# STM32MP25_CM33 register map
File version: 1.3
CPU: CM33 r0p1, little endian, MPU, FPU, vendor SysTick, 8 interrupt priority bits
Registers are 32-bit, read-write, reset 0x0 unless marked. A register's access mark holds for its fields unless they carry their own. Offsets are from the block's base; [hi:lo] are bit positions; {n}, {i} and the like mark numbered series; 'fields as' and 'values as' point back to an identical list.

## RCC (part 1 of 3) — RCC register block
Base 0x44200000
Same registers: RCC_S 0x54200000
0x00 RCC_SECCFGR0 — RCC secure configuration register 0
  [31:0] SEC — Secure attribute reference for local resource number x
    0=Secure and non-secure data accesses are granted to local resource number x; 1=Only secure data access is granted to local resource number x
0x04 RCC_SECCFGR1 — RCC secure configuration register 1
  [31:0] SEC — Secure attribute reference for the local resource number x
    values as RCC_SECCFGR0.SEC
0x08 RCC_SECCFGR2 — RCC secure configuration register 2
  [31:0] SEC — Secure attribute reference for the local resource number x
    0=Non-secure write access is allowed; 1=Only secure write access is allowed
0x0C RCC_SECCFGR3 — RCC secure configuration register 3
  [17:0] SEC — Secure attribute reference for the local resource number x
    0=Non-secure write access is allowed; 1=Secure write access is allowed
0x10 RCC_PRIVCFGR0 — RCC privileged configuration register 0
  [31:0] PRIV — Privileged attribute reference for local resource number x
    0=Privileged and unprivileged data accesses are granted to local resource number x; 1=Only privileged data access is granted to local resource number x
0x14 RCC_PRIVCFGR1 — RCC privileged configuration register 1
  [31:0] PRIV — Privileged attribute reference for the local resource number x
    values as RCC_PRIVCFGR0.PRIV
0x18 RCC_PRIVCFGR2 — RCC privileged configuration register 2
  fields as RCC_PRIVCFGR1
0x1C RCC_PRIVCFGR3 — RCC privileged configuration register 3
  [17:0] PRIV — Privileged attribute reference for the local resource number x
    values as RCC_PRIVCFGR0.PRIV
0x20 RCC_RCFGLOCKR0 — RCC resource configuration lock register 0
  [31:0] RLOCK — RCC local resource number x lock
    0=SECx in RCC_SECCFGR0 and PRIVx in RCC_PRIVCFGR0 are writable; 1=Writes to SECx in RCC_SECCFGR0 and PRIVx in RCC_PRIVCFGR0 are ignored
0x24 RCC_RCFGLOCKR1 — RCC resource configuration lock register 1
  [31:0] RLOCK — RCC local resource number x lock
    0=SEC(x - 32) in RCC_SECCFGR1 and PRIV(x - 32) in RCC_PRIVCFGR1 are writable; 1=Writes to SEC(x - 32) in RCC_SECCFGR1 and PRIV(x - 32) in RCC_PRIVCFGR1 are ignored
0x28 RCC_RCFGLOCKR2 — RCC resource configuration lock register 2
  [31:0] RLOCK — RCC local resource number x lock
    0=SEC(x - 64) in RCC_SECCFGR2 and PRIV(x - 64) in RCC_PRIVCFGR2 are writable; 1=Writes to SEC(x - 64) in RCC_SECCFGR2 and PRIV(x - 64) in RCC_PRIVCFGR2 are ignored
0x2C RCC_RCFGLOCKR3 — RCC resource configuration lock register 3
  [17:0] RLOCK — RCC local resource number x lock
    0=SEC(x - 96) in RCC_SECCFGR3 and PRIV(x - 96) in RCC_PRIVCFGR3 are writable; 1=Writes to SEC(x - 96) in RCC_SECCFGR3 and PRIV(x - 96) in RCC_PRIVCFGR3 are ignored
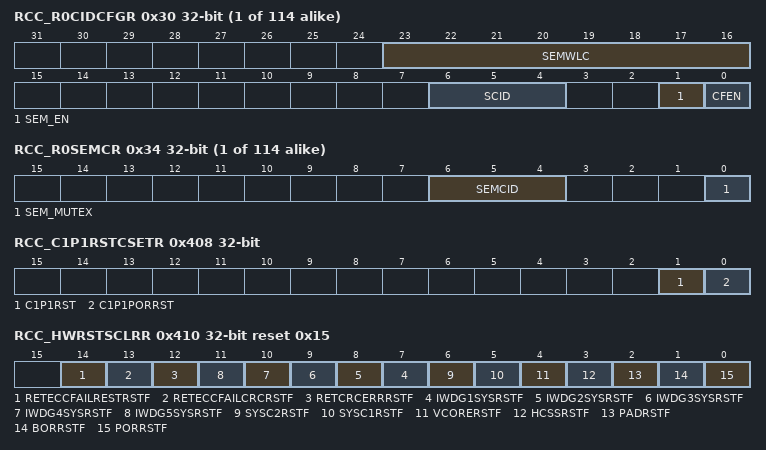
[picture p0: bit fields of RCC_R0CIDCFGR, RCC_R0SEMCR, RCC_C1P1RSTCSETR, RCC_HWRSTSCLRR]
{0x30+8i} RCC_R{i}CIDCFGR (i=0..113) — RCC resource {i} CID configuration register
  [23:16] SEMWLC — Semaphore white-list for compartment y
    0=Application running in compartment y cannot get access to local resource x through semaphore SEM_MUTEX; 1=Application running in compartment y can get access to local resource x through semaphore SEM_MUTEX
  [6:4] SCID — Static compartment ID
  [1] SEM_EN — Semaphore enable
    0=Access to local resource x is granted only if CID of the access equals to SCID; 1=Access to local resource x is granted only if SEM_MUTEX = 1, and CID of the access equals to SEMCID
  [0] CFEN — Static CID filter enable
    0=Compartment-based filtering is defined in RCC_RxCIDCFGR, and optionally RCC_RxSEMCR is disabled for local resource x; 1=Compartment-based filtering is defined in RCC_RxCIDCFGR, and optionally RCC_RxSEMCR is enabled for local resource x
{0x34+8i} RCC_R{i}SEMCR (i=0..113) — RCC resource {i} semaphore control register
  [6:4] SEMCID ro — Semaphore compartment ID
  [0] SEM_MUTEX — Semaphore mutex
    0=Reading 0 means that the semaphore is free; 1=Reading 1 means that the semaphore is taken
0x400 RCC_GRSTCSETR — RCC global reset control set register
  [0] SYSRST — System reset
    0=Writing 0 has no effect; 1=Writing 1 generates a system reset (see Figure80)
0x404 RCC_C1RSTCSETR — RCC CPU1 reset control set register
  [0] C1RST — CPU1 reset
    0=Writing 0 has no effect; 1=Writing 1 generates a CPU1 reset
0x408 RCC_C1P1RSTCSETR — RCC CPU1 processor core 1 reset control set register
  [1] C1P1RST — CPU1 processor core 1 reset
    0=Writing 0 has no effect; 1=Writing 1 generates a CPU1 processor core 1 reset
  [0] C1P1PORRST — CPU1 processor core 1 power-on reset
    0=Writing 0 has no effect; 1=Writing 1 generates a CPU1 processor core 1 power-on reset
0x40C RCC_C2RSTCSETR — RCC CPU2 reset control set register
  [0] C2RST — CPU2 reset
    0=Writing 0 has no effect; 1=Writing 1 generates a CPU2 reset
0x410 RCC_HWRSTSCLRR reset 0x15 — RCC hardware reset status clear register
  [14] RETECCFAILRESTRSTF — RETRAM ECC failure reset flag during system restoration phase
    0=Writing 0 has no effect; 1=Writing 1 clears the RETECCFAILRESTRSTF flag
  [13] RETECCFAILCRCRSTF — RETRAM ECC failure reset flag during the CRC computation phase
    0=Writing 0 has no effect; 1=Writing 1 clears the RETECCFAILCRCRSTF flag
  [12] RETCRCERRRSTF — RETRAM CRC error reset flag
    0=Writing 0 has no effect; 1=Writing 1 clears the RETCRCERRRSTF flag
  [n+6] IWDG{n}SYSRSTF (n=1..5) — IWDG{n} system reset flag
    0=Writing 0 has no effect; 1=Writing 1 clears the IWDG{n}SYSRSTF flag
  [6] SYSC2RSTF — CPU2 system reset flag
    0=Writing 0 has no effect; 1=Writing 1 clears the SYSC2RSTF flag
  [5] SYSC1RSTF — CPU1 system reset flag
    0=Writing 0 has no effect; 1=Writing 1 clears the SYSC1RSTF flag
  [4] VCORERSTF — Vless thansub>DDCOREless than/sub> reset flag
    0=Writing 0 has no effect; 1=Writing 1 clears the VCORERSTF flag
  [3] HCSSRSTF — HSE CSS reset flag
    0=Writing 0 has no effect; 1=Writing 1 clears the HCSSRSTF flag
  [2] PADRSTF — NRST reset flag
    0=Writing 0 has no effect; 1=Writing 1 clears the PADRSTF flag
  [1] BORRSTF — BOR reset flag
    0=Writing 0 has no effect; 1=Writing 1 clears the BORRSTF flag
  [0] PORRSTF — POR/PDR reset flag
    0=Writing 0 has no effect; 1=Writing 1 clears the PORRSTF flag
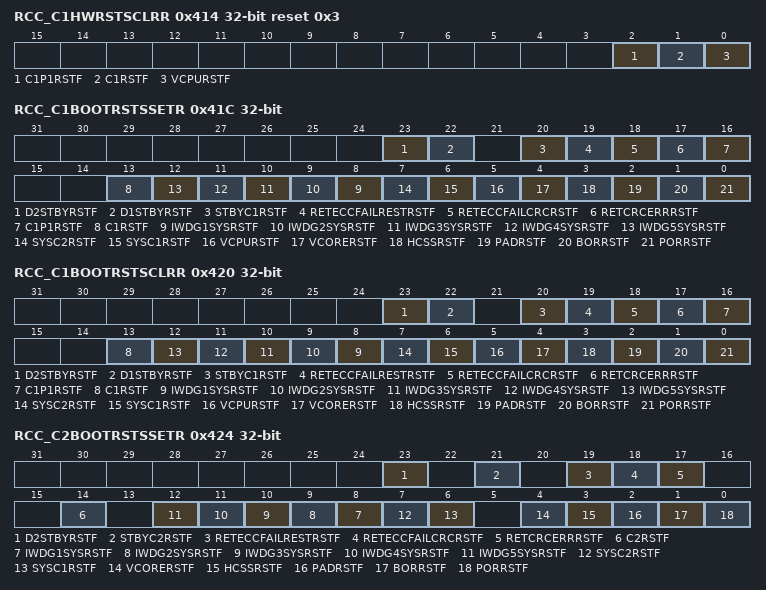
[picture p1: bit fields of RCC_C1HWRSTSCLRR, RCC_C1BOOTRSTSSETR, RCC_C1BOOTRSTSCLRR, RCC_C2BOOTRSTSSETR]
0x414 RCC_C1HWRSTSCLRR reset 0x3 — RCC CPU1 hardware reset status clear register
  [2] C1P1RSTF — CPU1 processor core 1 reset flag
    0=Writing 0 has no effect; 1=Writing 1 clears the C1P1RSTF flag
  [1] C1RSTF — CPU1 reset flag
    0=Writing 0 has no effect; 1=Writing 1 clears the C1RSTF flag
  [0] VCPURSTF — Vless thansub>DDCPUless than/sub> reset flag
    0=Writing 0 has no effect; 1=Writing 1 clears the VCPURSTF flag
0x418 RCC_C2HWRSTSCLRR reset 0x1 — RCC CPU2 hardware reset status clear register
  [0] C2RSTF — CPU2 reset flag
    0=Writing 0 has no effect; 1=Writing 1 clears the C2RSTF flag
0x41C RCC_C1BOOTRSTSSETR — RCC CPU1 boot reset status set register
  [23] D2STBYRSTF — D2 DStandby reset flag
    0=No effect; 1=Set the D2STBYRSTF bit
  [22] D1STBYRSTF — D1 DStandby reset flag
    0=No effect; 1=Set the D1STBYRSTF bit
  [20] STBYC1RSTF — CPU1 system Standby reset flag
    0=No effect; 1=Set the STBYC1RSTF bit
  [19] RETECCFAILRESTRSTF — RETRAM ECC failure reset flag during system restoration phase
    0=No effect; 1=Set the RETECCFAILRESTRSTF bit
  [18] RETECCFAILCRCRSTF — RETRAM ECC failure reset flag during the CRC computation phase
    0=No effect; 1=Set the RETECCFAILCRCRSTF bit
  [17] RETCRCERRRSTF — RETRAM CRC error reset flag
    0=No effect; 1=Set the RETCRCERRRSTF bit
  [16] C1P1RSTF — CPU1 processor core 1 reset flag
    0=No effect; 1=Set the C1P1RSTF bit
  [13] C1RSTF — CPU1 reset flag
    0=No effect; 1=Set the C1RSTF bit
  [n+7] IWDG{n}SYSRSTF (n=1..5) — IWDG{n} system reset flag
    0=No effect; 1=Set the IWDG{n}SYSRSTF bit
  [7] SYSC2RSTF — CPU2 system reset flag
    0=No effect; 1=Set the SYSC2RSTF bit
  [6] SYSC1RSTF — CPU1 system reset flag
    0=No effect; 1=Set the SYSC1RSTF bit
  [5] VCPURSTF — Vless thansub>DDCPUless than/sub> reset flag
    0=No effect; 1=Set the VCPURSTF bit
  [4] VCORERSTF — Vless thansub>DDCOREless than/sub> reset flag
    0=No effect; 1=Set the VCORERSTF bit
  [3] HCSSRSTF — HSE CSS reset flag
    0=No effect; 1=Set the HCSSRSTF bit
  [2] PADRSTF — NRST reset flag
    0=No effect; 1=Set the PADRSTF bit
  [1] BORRSTF — BOR reset flag
    0=No effect; 1=Set the BORRSTF bit
  [0] PORRSTF — POR/PDR reset flag
    0=No effect; 1=Set the PORRSTF bit
0x420 RCC_C1BOOTRSTSCLRR — RCC CPU1 boot reset status clear register
  [23] D2STBYRSTF — D2 DStandby reset flag
    0=No effect; 1=Clear the D2STBYRSTF bit
  [22] D1STBYRSTF — D1 DStandby reset flag
    0=No effect; 1=Clear the D1STBYRSTF bit
  [20] STBYC1RSTF — CPU1 system Standby reset flag
    0=No effect; 1=Clear the STBYC1RSTF bit
  [19] RETECCFAILRESTRSTF — RETRAM ECC failure reset flag during system restoration phase
    0=No effect; 1=Clear the RETECCFAILRESTRSTF bit
  [18] RETECCFAILCRCRSTF — RETRAM ECC failure reset flag during the CRC computation phase
    0=No effect; 1=Clear the RETECCFAILCRCRSTF bit
  [17] RETCRCERRRSTF — RETRAM CRC error reset flag
    0=No effect; 1=Clear the RETCRCERRRSTF bit
  [16] C1P1RSTF — CPU1 processor core 1 reset flag
    0=No effect; 1=Clear the C1P1RSTF bit
  [13] C1RSTF — CPU1 reset flag
    0=No effect; 1=Clear the C1RSTF bit
  [n+7] IWDG{n}SYSRSTF (n=1..5) — IWDG{n} system reset flag
    0=No effect; 1=Clear the IWDG{n}SYSRSTF bit
  [7] SYSC2RSTF — CPU2 system reset flag
    0=No effect; 1=Clear the SYSC2RSTF bit
  [6] SYSC1RSTF — CPU1 system reset flag
    0=No effect; 1=Clear the SYSC1RSTF bit
  [5] VCPURSTF — Vless thansub>DDCPUless than/sub> reset flag
    0=No effect; 1=Clear the VCPURSTF bit
  [4] VCORERSTF — Vless thansub>DDCOREless than/sub> reset flag
    0=No effect; 1=Clear the VCORERSTF bit
  [3] HCSSRSTF — HSE CSS reset flag
    0=No effect; 1=Clear the HCSSRSTF bit
  [2] PADRSTF — NRST reset flag
    0=No effect; 1=Clear the PADRSTF bit
  [1] BORRSTF — BOR reset flag
    0=No effect; 1=Clear the BORRSTF bit
  [0] PORRSTF — POR/PDR reset flag
    0=No effect; 1=Clear the PORRSTF bit
0x424 RCC_C2BOOTRSTSSETR — RCC CPU2 boot reset status set register
  [23] D2STBYRSTF — D2 DStandby reset flag
    0=No effect; 1=Set the D2STBYRSTF bit
  [21] STBYC2RSTF — CPU2 system Standby reset flag
    0=No effect; 1=Set the STBYC2RSTF bit
  [19] RETECCFAILRESTRSTF — RETRAM ECC failure reset flag during system restoration phase
    0=No effect; 1=Set the RETECCFAILRESTRSTF bit
  [18] RETECCFAILCRCRSTF — RETRAM ECC failure reset flag during the CRC computation phase
    0=No effect; 1=Set the RETECCFAILCRCRSTF bit
  [17] RETCRCERRRSTF — RETRAM CRC error reset flag
    0=No effect; 1=Set the RETCRCERRRSTF bit
  [14] C2RSTF — CPU2 reset flag
    0=No effect; 1=Set the C2RSTF bit
  [n+7] IWDG{n}SYSRSTF (n=1..5) — IWDG{n} system reset flag
    0=No effect; 1=Set the IWDG{n}SYSRSTF bit
  [7] SYSC2RSTF — CPU2 system reset flag
    0=No effect; 1=Set the SYSC2RSTF bit
  [6] SYSC1RSTF — CPU1 system reset flag
    0=No effect; 1=Set the SYSC1RSTF bit
  [4] VCORERSTF — Vless thansub>DDCOREless than/sub> reset flag
    0=No effect; 1=Set the VCORERSTF bit
  [3] HCSSRSTF — HSE CSS reset flag
    0=No effect; 1=Set the HCSSRSTF bit
  [2] PADRSTF — NRST reset flag
    0=No effect; 1=Set the PADRSTF bit
  [1] BORRSTF — BOR reset flag
    0=No effect; 1=Set the BORRSTF bit
  [0] PORRSTF — POR/PDR reset flag
    0=No effect; 1=Set the PORRSTF bit
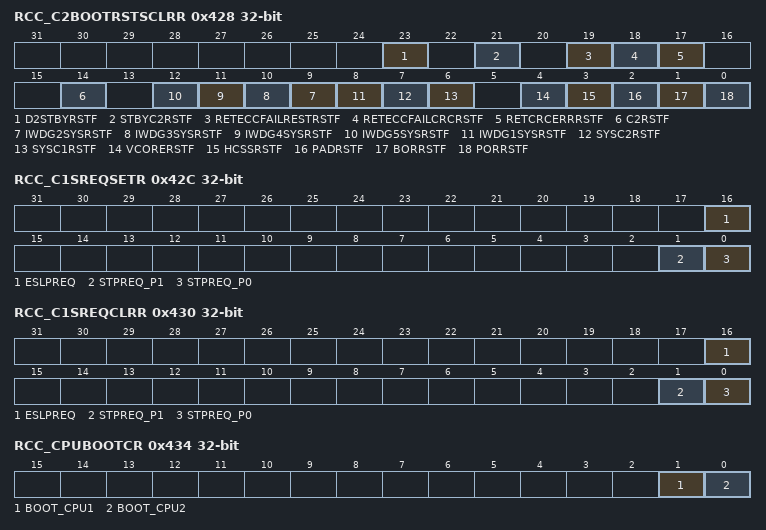
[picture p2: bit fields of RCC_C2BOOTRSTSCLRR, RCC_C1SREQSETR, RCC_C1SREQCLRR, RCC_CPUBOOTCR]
0x428 RCC_C2BOOTRSTSCLRR — RCC CPU2 boot reset status clear register
  [23] D2STBYRSTF — D2 DStandby reset flag
    0=No effect; 1=Clear the D2STBYRSTF bit
  [21] STBYC2RSTF — CPU2 system Standby reset flag
    0=No effect; 1=Clear the STBYC2RSTF bit
  [19] RETECCFAILRESTRSTF — RETRAM ECC failure reset flag during system restoration phase
    0=No effect; 1=Clear the RETECCFAILRESTRSTF bit
  [18] RETECCFAILCRCRSTF — RETRAM ECC failure reset flag during the CRC computation phase
    0=No effect; 1=Clear the RETECCFAILCRCRSTF bit
  [17] RETCRCERRRSTF — RETRAM CRC error reset flag
    0=No effect; 1=Clear the RETCRCERRRSTF bit
  [14] C2RSTF — CPU2 reset flag
    0=No effect; 1=Clear the C2RSTF bit
  [n+7] IWDG{n}SYSRSTF (n=2..5) — IWDG{n} reset flag
    0=No effect; 1=Clear the IWDG{n}SYSRSTF bit
  [8] IWDG1SYSRSTF — IWDG1 system reset flag
    0=No effect; 1=Clear the IWDG1SYSRSTF bit
  [7] SYSC2RSTF — CPU2 system reset flag
    0=No effect; 1=Clear the SYSC2RSTF bit
  [6] SYSC1RSTF — CPU1 system reset flag
    0=No effect; 1=Clear the SYSC1RSTF bit
  [4] VCORERSTF — Vless thansub>DDCOREless than/sub> reset flag
    0=No effect; 1=Clear the VCORERSTF bit
  [3] HCSSRSTF — HSE CSS reset flag
    0=No effect; 1=Clear the HCSSRSTF bit
  [2] PADRSTF — NRST reset flag
    0=No effect; 1=Clear the PADRSTF bit
  [1] BORRSTF — BOR reset flag
    0=No effect; 1=Clear the BORRSTF bit
  [0] PORRSTF — POR/PDR reset flag
    0=No effect; 1=Clear the PORRSTF bit
0x42C RCC_C1SREQSETR — RCC CPU1 stop request set register
  [16] ESLPREQ — Enhanced CSleep request for CPU1 subsystem
    0=Writing 0 has no effect; 1=Writing 1 sets the ESLPREQ bit
  [1] STPREQ_P1 — Stop request for CPU1 processor core 1
    0=Writing 0 has no effect; 1=Writing 1 sets the STPREQ_P1 bit
  [0] STPREQ_P0 — Stop request for CPU1 processor core 0
    0=Writing 0 has no effect; 1=Writing 1 sets the STPREQ_P0 bit
0x430 RCC_C1SREQCLRR — RCC CPU1 stop request clear register
  [16] ESLPREQ — Enhanced CSleep request for CPU1 subsystem
    0=Writing 0 has no effect; 1=Writing 1 clears the ESLPREQ bit
  [1] STPREQ_P1 — Stop request for CPU1 processor core 1
    0=Writing 0 has no effect; 1=Writing 1 clears the STPREQ_P1 bit
  [0] STPREQ_P0 — Stop request for CPU1 processor core 0
    0=Writing 0 has no effect; 1=Writing 1 clears the STPREQ_P0 bit
0x434 RCC_CPUBOOTCR — RCC CPU boot control register
  [1] BOOT_CPU1 — CPU1 boot
    0=The CPU1 is set in HOLD_BOOT when the next CPU1 reset occurs; 1=The CPU1 is not in HOLD_BOOT mode when the next CPU1 reset occurs
  [0] BOOT_CPU2 — CPU2 to boot
    0=The CPU2 is set in HOLD_BOOT when the next CPU2 core reset occurs; 1=The CPU2 is not in HOLD_BOOT mode when the next CPU2 core reset occurs
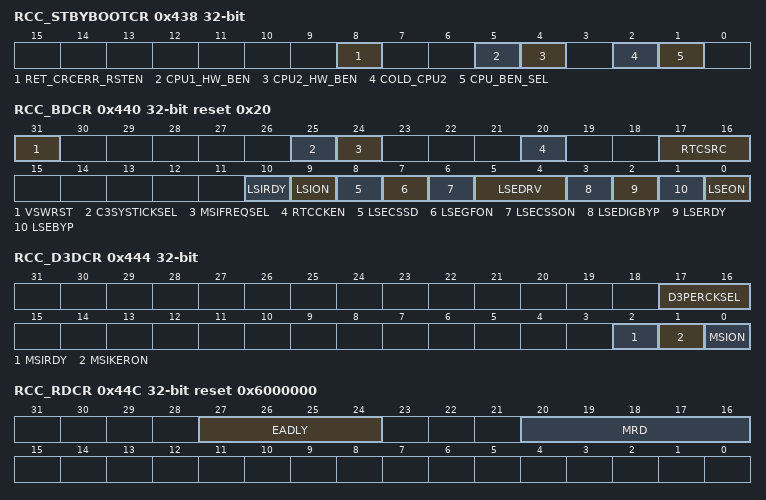
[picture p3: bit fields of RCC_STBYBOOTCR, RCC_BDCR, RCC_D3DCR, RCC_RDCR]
0x438 RCC_STBYBOOTCR rw-once — RCC standby boot control register
  [8] RET_CRCERR_RSTEN rw — RETRAM CRC error system reset enable
    0=RETRAM CRC error does not trigger a system reset (default after reset); 1=RETRAM CRC error triggers a system reset
  [5] CPU1_HW_BEN ro — CPU1 hardware boot enable
    0=CPU1 remains in HOLD_BOOT state; 1=CPU1 is allowed to restart
  [4] CPU2_HW_BEN ro — CPU2 hardware boot enable
    0=CPU2 remains in HOLD_BOOT state; 1=CPU2 is allowed to restart
  [2] COLD_CPU2 — CPU2 cold boot
    0=CPU1 is the cold boot CPU; 1=CPU2 is the cold boot CPU
  [1] CPU_BEN_SEL rw — CPU boot select
    0=CPU1 restarts first (default after reset); 1=CPU2 restarts first
0x43C RCC_LEGBOOTCR rw-once — RCC legacy boot control register
  [0] LEGACY_BEN — Enable of the legacy selection mode to choose the first CPU to boot
    0=The legacy selection mode is disabled (default after reset); 1=The legacy selection mode is enabled
0x440 RCC_BDCR rw-once reset 0x20 — RCC backup domain control register
  [31] VSWRST rw — Vless thansub>SWless than/sub> domain software reset
    0=Reset not activated (default after backup domain reset); 1=Resets the entire Vless thansub>SWless than/sub> domain
  [25] C3SYSTICKSEL rw — CPU3 SysTick clock select
    0=CPU3 SysTick clock is LSI (default after backup domain reset); 1=CPU3 SysTick clock is LSE
  [24] MSIFREQSEL rw — MSI frequency selection
    0=MSI frequency is 4 MHz (default after backup domain reset); 1=MSI frequency is 16 MHz
  [20] RTCCKEN rw — RTC clock enable
    0=rtc_ck clock disabled (default after backup domain reset); 1=rtc_ck clock enabled
  [17:16] RTCSRC — RTC clock source selection
    0=No clock (default after backup domain reset); 1=LSE clock used as RTC clock; 2=LSI clock used as RTC clock; 3=HSE clock divided by RTCDIV value used as RTC clock
  [10] LSIRDY ro — LSI oscillator ready
    0=LSI oscillator not ready (default after reset); 1=LSI oscillator ready
  [9] LSION rw — LSI oscillator enabled
    0=LSI oscillator off (default after backup domain reset); 1=LSI oscillator on
  [8] LSECSSD ro — LSE CSS failure detection
    0=No failure detected on 32 kHz oscillator (default after backup domain reset); 1=Failure detected on 32 kHz oscillator
  [7] LSEGFON rw — LSE clock glitch filter enable
    0=LSE clock glitch filter disabled; 1=LSE clock glitch filter enabled
  [6] LSECSSON rw — LSE CSS enable
    0=CSS on 32 kHz oscillator off (default after backup domain reset); 1=CSS on 32 kHz oscillator on
  [5:4] LSEDRV rw — LSE oscillator driving capability
    0=Lowest drive; 1=Medium-low drive; 2=Medium-high drive (default after backup domain reset); 3=Highest drive
  [3] LSEDIGBYP rw — LSE digital bypass
    0=LSE in analog bypass mode (default after backup domain reset); 1=LSE in digital bypass mode
  [2] LSERDY ro — LSE oscillator ready
    0=LSE oscillator not ready (default after backup domain reset); 1=LSE oscillator ready
  [1] LSEBYP rw — LSE oscillator bypass
    0=LSE oscillator not bypassed (default after backup domain reset); 1=LSE oscillator bypassed
  [0] LSEON rw — LSE oscillator enable
    0=LSE oscillator off (default after backup domain reset); 1=LSE oscillator on
0x444 RCC_D3DCR — RCC D3 domain control register
  [17:16] D3PERCKSEL — D3 peripheral local bus clock select
    0=MSI kernel clock used as D3 peripheral bus clock interface; 1=LSI clock used as D3 peripheral bus clock interface; 2=LSE clock used as D3 peripheral bus clock interface
  [2] MSIRDY ro — MSI clock ready flag
    0=MSI clock is not ready (default after reset); 1=MSI clock is ready
  [1] MSIKERON — Set by software to force the MSI on, even in Stop mode, in order to be quickly available as kernel clock for some peripherals.
    0=No effect; 1=Set the MSIKERON bit
  [0] MSION — MSI oscillator enable
    0=MSI oscillator off (default after reset); 1=MSI oscillator on
0x448 RCC_D3DSR ro — RCC D3 domain status register
  [1:0] D3STATE — D3 domain state
    0=D3 domain in reset state (default after reset); 1=D3 domain in system state (flexclkgen clocking); 2=D3 domain in clock switching state; 3=D3 domain in local state (D3 local clocking)
0x44C RCC_RDCR reset 0x6000000 — RCC reset duration control register
  [27:24] EADLY — External access delays
    0=No extra delay added by boot ROM; 1=100 us; 2=200 us; 3=500 us; 4=1 ms; 5=2 ms; 6=5 ms (default after reset); 7=10 ms; 8=20 ms; 9=50 ms; 10=100 ms; 11=200 ms; 12=500 ms; 13=1 s; 14=2 s; 15=5 s
  [20:16] MRD — Minimum reset duration
    0=NRST low-pulse duration is guaranteed by the pulse stretcher of the pin; 1=The guaranteed NRST low-pulse duration is about 1 ms (1 x 32 lsi_ck cycles); 2=The guaranteed NRST low-pulse duration is about 2 ms (2 x 32 lsi_ck cycles); 31=The guaranteed NRST low-pulse duration is about 31 ms (31 x 32 lsi_ck cycles)
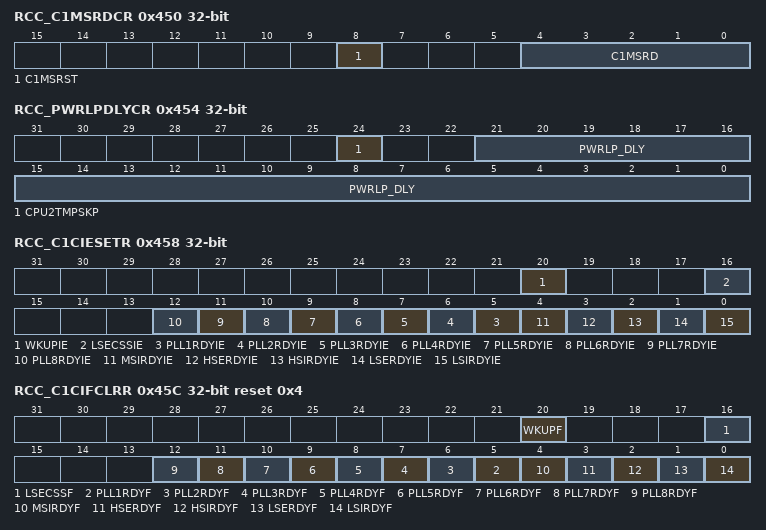
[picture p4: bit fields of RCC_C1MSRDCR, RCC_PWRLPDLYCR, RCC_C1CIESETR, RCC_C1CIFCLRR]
0x450 RCC_C1MSRDCR — RCC C1MS reset delay control register
  [8] C1MSRST — Trigger low-level pulse on NRSTC1MS pin
    0=Reading 0 means that the NRSTC1MS level is high (inactive) (default after reset); 1=Writing 1 triggers a low-level pulse on NRSTC1MS according to C1MSRD value
  [4:0] C1MSRD — Minimum Standby reset duration
    0=No pulse on NRSTC1MS (default after reset); 1=The guaranteed NRSTC1MS low-pulse duration is about 1 ms (1 x 32 lsi_ck cycles); 2=The guaranteed NRSTC1MS low-pulse duration is about 2 ms (2 x 32 lsi_ck cycles); 31=The guaranteed NRSTC1MS low-pulse duration is about 31 ms (31 x 32 lsi_ck cycles)
0x454 RCC_PWRLPDLYCR — RCC PWR_LP delay control register
  [24] CPU2TMPSKP — Skip of PWR_LP delay for CPU2
    0=The CPU2 clock restore sequence waits for the PWR_LP delay before activating power consuming elements (default after reset); 1=The CPU2 clock restore sequence runs the PWR_LP delay, but did not wait for the delay to elapse before activating power consuming elements
  [21:0] PWRLP_DLY — PWR_LP delay value
    0=PWR_LP delay bypassed (default after reset); 1=PWR_LP delay of one 64 MHz HSI period (LSMCU = 0) or two HSI periods; 0x3FFFFF=PWR_LP delay of about 65
0x458 RCC_C1CIESETR — RCC CPU1 clock source interrupt enable set register
  [20] WKUPIE — CPU1 wake-up from CStop interrupt enable
    0=Wake-up interrupt disabled (default after reset); 1=Wake-up interrupt enabled
  [16] LSECSSIE — LSE clock security system interrupt enable
    0=LSE CSS interrupt disabled (default after reset); 1=LSE CSS interrupt enabled
  [n+4] PLL{n}RDYIE (n=1..8) — PLL{n} ready interrupt enable
    0=PLL{n} lock interrupt disabled (default after reset); 1=PLL{n} lock interrupt enabled
  [4] MSIRDYIE — MSI ready interrupt enable
    0=MSI ready interrupt disabled (default after reset); 1=MSI ready interrupt enabled
  [3] HSERDYIE — HSE ready interrupt enable
    0=HSE ready interrupt disabled (default after reset); 1=HSE ready interrupt enabled
  [2] HSIRDYIE — HSI ready interrupt enable
    0=HSI ready interrupt disabled (default after reset); 1=HSI ready interrupt enabled
  [1] LSERDYIE — LSE ready interrupt enable
    0=LSE ready interrupt disabled (default after reset); 1=LSE ready interrupt enabled
  [0] LSIRDYIE — LSI ready interrupt enable
    0=LSI ready interrupt disabled (default after reset); 1=LSI ready interrupt enabled
0x45C RCC_C1CIFCLRR reset 0x4 — RCC CPU1 clock source interrupt flag clear register
  [20] WKUPF — CPU1 wake-up from CStop interrupt flag
    0=No wake-up interrupt pending (default after reset); 1=Wake-up interrupt pending
  [16] LSECSSF — LSE CSS interrupt flag
    0=No failure detected on the external 32 kHz oscillator (default after reset); 1=A failure is detected on the external 32 kHz oscillator
  [n+4] PLL{n}RDYF (n=1..8) — PLL{n} ready interrupt flag
    0=No clock ready interrupt caused by PLL{n} lock (default after reset); 1=Clock ready interrupt caused by PLL{n} lock
  [4] MSIRDYF — MSI ready interrupt flag
    0=No clock ready interrupt caused by the MSI (default after reset); 1=Clock ready interrupt caused by the MSI
  [3] HSERDYF — HSE ready interrupt flag
    0=No clock ready interrupt caused by the HSE (default after reset); 1=Clock ready interrupt caused by the HSE
  [2] HSIRDYF — HSI ready interrupt flag
    0=No clock ready interrupt caused by the HSI (default after reset); 1=Clock ready interrupt caused by the HSI
  [1] LSERDYF — LSE ready interrupt flag
    0=No clock ready interrupt caused by the LSE (default after reset); 1=Clock ready interrupt caused by the LSE
  [0] LSIRDYF — LSI ready interrupt flag
    0=No clock ready interrupt caused by the LSI (default after reset); 1=Clock ready interrupt caused by the LSI
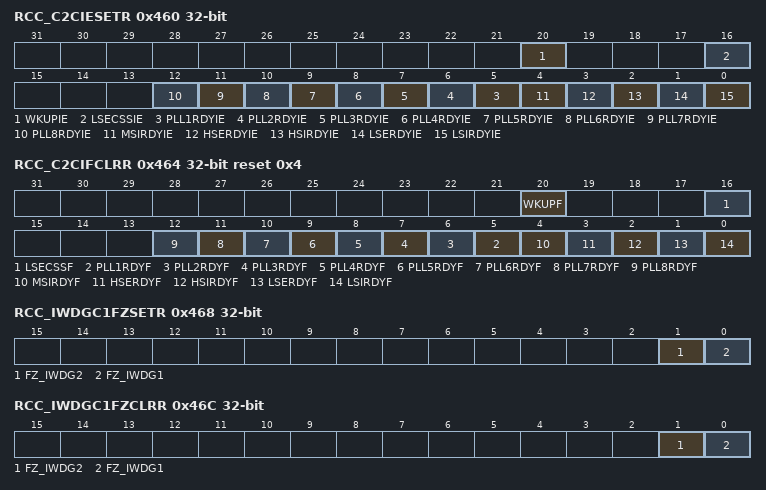
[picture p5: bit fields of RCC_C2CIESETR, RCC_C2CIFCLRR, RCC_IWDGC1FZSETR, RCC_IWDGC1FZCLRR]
0x460 RCC_C2CIESETR — RCC CPU2 clock source interrupt enable set register
  [20] WKUPIE — CPU2 wake-up from CStop Interrupt Enable
    values as RCC_C1CIESETR.WKUPIE
  [16] LSECSSIE — LSE CSS interrupt enable
    values as RCC_C1CIESETR.LSECSSIE
  [n+4] PLL{n}RDYIE (n=1..8) — PLL{n} ready interrupt enable
    values as RCC_C1CIESETR.PLL1RDYIE
  [4] MSIRDYIE — MSI ready interrupt enable
    values as RCC_C1CIESETR.MSIRDYIE
  [3] HSERDYIE — HSE ready interrupt enable
    values as RCC_C1CIESETR.HSERDYIE
  [2] HSIRDYIE — HSI ready interrupt enable
    values as RCC_C1CIESETR.HSIRDYIE
  [1] LSERDYIE — LSE ready interrupt enable
    values as RCC_C1CIESETR.LSERDYIE
  [0] LSIRDYIE — LSI ready interrupt enable
    values as RCC_C1CIESETR.LSIRDYIE
0x464 RCC_C2CIFCLRR reset 0x4 — RCC CPU2 clock source interrupt flag clear register
  [20] WKUPF — CPU2 wake-up from CStop interrupt flag
    values as RCC_C1CIFCLRR.WKUPF
  [16] LSECSSF — LSE clock security system interrupt flag
    values as RCC_C1CIFCLRR.LSECSSF
  [n+4] PLL{n}RDYF (n=1..8) — PLL{n} ready interrupt flag
    values as RCC_C1CIFCLRR.PLL1RDYF
  [4] MSIRDYF — MSI ready interrupt flag
    values as RCC_C1CIFCLRR.MSIRDYF
  [3] HSERDYF — HSE ready interrupt flag
    values as RCC_C1CIFCLRR.HSERDYF
  [2] HSIRDYF — HSI ready interrupt flag
    values as RCC_C1CIFCLRR.HSIRDYF
  [1] LSERDYF — LSE ready interrupt flag
    values as RCC_C1CIFCLRR.LSERDYF
  [0] LSIRDYF — LSI ready interrupt flag
    values as RCC_C1CIFCLRR.LSIRDYF
0x468 RCC_IWDGC1FZSETR — RCC IWDG CPU1 clock freeze set register
  [1] FZ_IWDG2 — Freeze of IWDG2 clock
    0=Writing 0 has no effect; 1=Writing 1 freezes IWDG2 clock
  [0] FZ_IWDG1 — Freeze of IWDG1 clock
    0=Writing 0 has no effect; 1=Writing 1 freezes IWDG1 clock
0x46C RCC_IWDGC1FZCLRR — RCC IWDG CPU1 clock freeze clear register
  [1] FZ_IWDG2 — Unfreeze IWDG2 clock
    0=Writing 0 has no effect; 1=Writing 1 unfreezes IWDG2 clock
  [0] FZ_IWDG1 — Unfreeze IWDG1 clock
    0=Writing 0 has no effect; 1=Writing 1 unfreezes IWDG1 clock
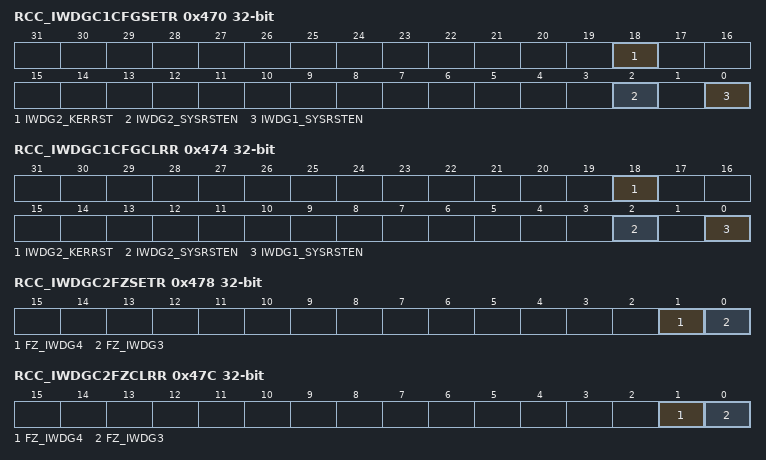
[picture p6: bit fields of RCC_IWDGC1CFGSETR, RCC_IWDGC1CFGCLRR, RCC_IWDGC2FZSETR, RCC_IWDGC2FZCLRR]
0x470 RCC_IWDGC1CFGSETR — RCC IWDG CPU1 configuration set register
  [18] IWDG2_KERRST — IWDG2 kernel reset
    0=Writing 0 has no effect; 1=Writing 1 activates IWDG2 kernel reset Reading 1 means IWDG2 kernel reset is active
  [2] IWDG2_SYSRSTEN — Enable of IWDG2 timeout event to reset the application
    0=Writing 0 has no effect; 1=Writing 1 enables IWDG2 timeout event to reset the application
  [0] IWDG1_SYSRSTEN — Enable of IWDG1 timeout event to reset the application
    0=Writing 0 has no effect; 1=Writing 1 enables IWDG1 timeout event to reset the application when CPU1 is not the trusted agent
0x474 RCC_IWDGC1CFGCLRR — RCC IWDG CPU1 configuration clear register
  [18] IWDG2_KERRST — IWDG2 kernel reset
    0=Writing 0 has no effect; 1=Writing 1 deactivates IWDG2 kernel reset
  [2] IWDG2_SYSRSTEN — Clear of IWDG2 timeout event to reset the application
    0=Writing 0 has no effect; 1=Writing 1 clears IWDG2 timeout event to reset the application
  [0] IWDG1_SYSRSTEN — Clear of IWDG1 timeout event to reset the application
    0=Writing 0 has no effect; 1=Writing 1 clears IWDG1 timeout event to reset the application when CPU1 is not the trusted agent
0x478 RCC_IWDGC2FZSETR — RCC IWDG CPU2 clock freeze set register
  [1] FZ_IWDG4 — Freeze of IWDG4 clock
    0=Writing 0 has no effect; 1=Writing 1 freezes IWDG4 clock
  [0] FZ_IWDG3 — Freeze of IWDG3 clock
    0=Writing 0 has no effect; 1=Writing 1 freezes IWDG3 clock
0x47C RCC_IWDGC2FZCLRR — RCC IWDG CPU2 clock freeze clear register
  [1] FZ_IWDG4 — Unfreeze of IWDG4 clock
    0=Writing 0 has no effect; 1=Writing 1 unfreezes the IWDG4 clock
  [0] FZ_IWDG3 — Unfreeze of IWDG3 clock
    0=Writing 0 has no effect; 1=Writing 1 unfreezes IWDG3 clock
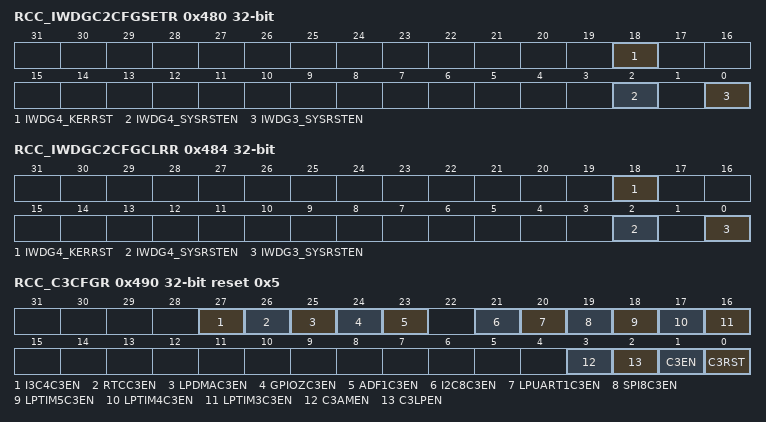
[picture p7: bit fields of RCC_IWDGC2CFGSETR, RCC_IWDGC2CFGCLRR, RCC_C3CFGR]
0x480 RCC_IWDGC2CFGSETR — RCC IWDG CPU2 configuration set register
  [18] IWDG4_KERRST — IWDG4 kernel reset
    0=Writing 0 has no effect; 1=Writing 1 activates IWDG4 kernel reset
  [2] IWDG4_SYSRSTEN — Enable of IWDG4 timeout event to reset the application
    0=Writing 0 has no effect; 1=Writing 1 enables IWDG4 timeout event to reset the application
  [0] IWDG3_SYSRSTEN — Enable of IWDG3 timeout event to reset the application
    0=Writing 0 has no effect; 1=Writing 1 enables IWDG3 timeout event to reset the application when CPU1 is not the trusted agent
0x484 RCC_IWDGC2CFGCLRR — RCC IWDG CPU2 configuration clear register
  [18] IWDG4_KERRST — IWDG4 kernel reset
    0=Writing 0 has no effect; 1=Writing 1 deactivates IWDG4 kernel reset
  [2] IWDG4_SYSRSTEN — Clear of IWDG4 timeout event to reset the application
    0=Writing 0 has no effect; 1=Writing 1 clears IWDG4 timeout event to reset the application
  [0] IWDG3_SYSRSTEN — Clear of IWDG3 timeout event to reset the application
    0=Writing 0 has no effect; 1=Writing 1 clears IWDG3 timeout event to reset the application when CPU1 is not the trusted agent
0x488 RCC_IWDGC3CFGSETR — RCC IWDG CPU3 configuration set register
  [0] IWDG5_SYSRSTEN — Enable of IWDG5 timeout event to reset the application
    0=Writing 0 has no effect; 1=Writing 1 enables IWDG5 timeout event to reset the application
0x48C RCC_IWDGC3CFGCLRR — RCC IWDG CPU3 configuration clear register
  [0] IWDG5_SYSRSTEN — Clear of IWDG5 timeout event to reset the application
    0=Writing 0 has no effect; 1=Writing 1 clears IWDG5 timeout event to reset the application
0x490 RCC_C3CFGR reset 0x5 — RCC CPU3 configuration register
  [27] I3C4C3EN — I3C4 allocation to CPU3 enable
    0=Writing 0 disables I3C4 allocation to CPU3; 1=Writing 1 enables I3C4 allocation to CPU3
  [26] RTCC3EN — RTC allocation to CPU3 enable
    0=Writing 0 disables RTC allocation to CPU3; 1=Writing 1 enables RTC allocation to CPU3
  [25] LPDMAC3EN — LPDMA1 allocation to CPU3 enable
    0=Writing 0 disables LPDMA1 allocation to CPU3; 1=Writing 1 enables LPDMA1 allocation to CPU3
  [24] GPIOZC3EN — GPIOZ allocation to CPU3 enable
    0=Writing 0 disables GPIOZ allocation to CPU3; 1=Writing 1 enables GPIOZ allocation to CPU3
  [23] ADF1C3EN — ADF1 allocation to CPU3 enable
    0=Writing 0 disables ADF1 allocation to CPU3; 1=Writing 1 enables ADF1 allocation to CPU3
  [21] I2C8C3EN — I2C8 allocation to CPU3 enable
    0=Writing 0 disables I2C8 allocation to CPU3; 1=Writing 1 enables I2C8 allocation to CPU3
  [20] LPUART1C3EN — LPUART1 allocation to CPU3 enable
    0=Writing 0 disables LPUART1 allocation to CPU3; 1=Writing 1 enables LPUART1 allocation to CPU3
  [19] SPI8C3EN — SPI8 allocation to CPU3 enable
    0=Writing 0 disables SPI8 allocation to CPU3; 1=Writing 1 enables SPI8 allocation to CPU3
  [18] LPTIM5C3EN — LPTIM5 allocation to CPU3 enable
    0=Writing 0 disables LPTIM5 allocation to CPU3; 1=Writing 1 enables LPTIM5 allocation to CPU3
  [17] LPTIM4C3EN — LPTIM4 allocation to CPU3 enable
    0=Writing 0 disables LPTIM4 allocation to CPU3; 1=Writing 1 enables LPTIM4 allocation to CPU3
  [16] LPTIM3C3EN — LPTIM3 allocation to CPU3 enable
    0=Writing 0 disables LPTIM3 allocation to CPU3; 1=Writing 1 enables LPTIM3 allocation to CPU3
  [3] C3AMEN — CPU3 autonomous clock mode enable
    0=Writing 0 disables autonomous clock mode; 1=Writing 1 enables autonomous clock mode
  [2] C3LPEN — CPU3 peripheral clock enable during CSleep
    0=Writing 0 disables the peripheral clocks in CSleep; 1=Writing 1 enables the peripheral clocks in CSleep
  [1] C3EN — CPU3 peripheral clocks enable
    0=Writing 0 disables the peripheral clocks; 1=Writing 1 enables the peripheral clocks
  [0] C3RST — CPU3 reset
    0=Writing 0 releases the block reset; 1=Writing 1 asserts the block reset
